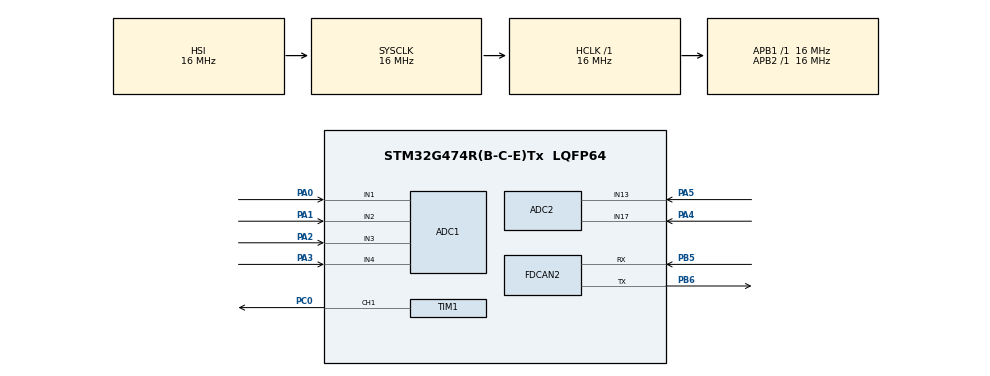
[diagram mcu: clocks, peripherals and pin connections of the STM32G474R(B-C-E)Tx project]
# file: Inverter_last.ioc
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ADC1.Channel-0\#ChannelRegularConversion=ADC_CHANNEL_1
ADC1.Channel-1\#ChannelRegularConversion=ADC_CHANNEL_2
ADC1.Channel-2\#ChannelRegularConversion=ADC_CHANNEL_3
ADC1.Channel-3\#ChannelRegularConversion=ADC_CHANNEL_4
ADC1.NbrOfConversion=4
ADC1.NbrOfConversionFlag=1
ADC1.OffsetNumber-0\#ChannelRegularConversion=ADC_OFFSET_NONE
ADC1.OffsetNumber-1\#ChannelRegularConversion=ADC_OFFSET_NONE
ADC1.OffsetNumber-2\#ChannelRegularConversion=ADC_OFFSET_NONE
ADC1.OffsetNumber-3\#ChannelRegularConversion=ADC_OFFSET_NONE
ADC1.Rank-0\#ChannelRegularConversion=1
ADC1.Rank-1\#ChannelRegularConversion=2
ADC1.Rank-2\#ChannelRegularConversion=3
ADC1.Rank-3\#ChannelRegularConversion=4
ADC1.SamplingTime-0\#ChannelRegularConversion=ADC_SAMPLETIME_2CYCLES_5
ADC1.SamplingTime-1\#ChannelRegularConversion=ADC_SAMPLETIME_2CYCLES_5
ADC1.SamplingTime-2\#ChannelRegularConversion=ADC_SAMPLETIME_2CYCLES_5
ADC1.SamplingTime-3\#ChannelRegularConversion=ADC_SAMPLETIME_2CYCLES_5
ADC1.master=1
ADC2.Channel-0\#ChannelRegularConversion=ADC_CHANNEL_17
ADC2.Channel-1\#ChannelRegularConversion=ADC_CHANNEL_13
ADC2.ContinuousConvMode=ENABLE
ADC2.DMAContinuousRequests=ENABLE
ADC2.EOCSelection=ADC_EOC_SEQ_CONV
ADC2.NbrOfConversion=2
ADC2.NbrOfConversionFlag=1
ADC2.OffsetNumber-0\#ChannelRegularConversion=ADC_OFFSET_NONE
ADC2.OffsetNumber-1\#ChannelRegularConversion=ADC_OFFSET_NONE
ADC2.Rank-0\#ChannelRegularConversion=1
ADC2.Rank-1\#ChannelRegularConversion=2
ADC2.SamplingTime-0\#ChannelRegularConversion=ADC_SAMPLETIME_2CYCLES_5
ADC2.SamplingTime-1\#ChannelRegularConversion=ADC_SAMPLETIME_2CYCLES_5
Dma.ADC1.0.Direction=DMA_PERIPH_TO_MEMORY
Dma.ADC1.0.EventEnable=DISABLE
Dma.ADC1.0.Instance=DMA1_Channel1
Dma.ADC1.0.MemDataAlignment=DMA_MDATAALIGN_WORD
Dma.ADC1.0.MemInc=DMA_MINC_ENABLE
Dma.ADC1.0.Mode=DMA_NORMAL
Dma.ADC1.0.PeriphDataAlignment=DMA_PDATAALIGN_WORD
Dma.ADC1.0.PeriphInc=DMA_PINC_DISABLE
Dma.ADC1.0.Polarity=HAL_DMAMUX_REQ_GEN_RISING
Dma.ADC1.0.Priority=DMA_PRIORITY_LOW
Dma.ADC1.0.RequestNumber=1
Dma.ADC1.0.SignalID=NONE
Dma.ADC1.0.SyncEnable=DISABLE
Dma.ADC1.0.SyncPolarity=HAL_DMAMUX_SYNC_NO_EVENT
Dma.ADC1.0.SyncRequestNumber=1
Dma.ADC1.0.SyncSignalID=NONE
Dma.ADC2.1.Direction=DMA_PERIPH_TO_MEMORY
Dma.ADC2.1.EventEnable=DISABLE
Dma.ADC2.1.Instance=DMA1_Channel2
Dma.ADC2.1.MemDataAlignment=DMA_MDATAALIGN_WORD
Dma.ADC2.1.MemInc=DMA_MINC_ENABLE
Dma.ADC2.1.Mode=DMA_NORMAL
Dma.ADC2.1.PeriphDataAlignment=DMA_PDATAALIGN_WORD
Dma.ADC2.1.PeriphInc=DMA_PINC_DISABLE
Dma.ADC2.1.Polarity=HAL_DMAMUX_REQ_GEN_RISING
Dma.ADC2.1.Priority=DMA_PRIORITY_LOW
Dma.ADC2.1.RequestNumber=1
Dma.ADC2.1.SignalID=NONE
Dma.ADC2.1.SyncEnable=DISABLE
Dma.ADC2.1.SyncPolarity=HAL_DMAMUX_SYNC_NO_EVENT
Dma.ADC2.1.SyncRequestNumber=1
Dma.ADC2.1.SyncSignalID=NONE
Dma.Request0=ADC1
Dma.Request1=ADC2
FDCAN2.CalculateBaudRateNominal=200000
FDCAN2.CalculateTimeBitNominal=5000
FDCAN2.CalculateTimeQuantumNominal=1000.0
FREERTOS.Tasks01=defaultTask,0,128,StartDefaultTask,Default,NULL,Dynamic,NULL,NULL;myTask02,-3,128,StartTask02,Default,NULL,Dynamic,NULL,NULL
FREERTOS.configUSE_NEWLIB_REENTRANT=1
Mcu.Family=STM32G4
Mcu.Name=STM32G474R(B-C-E)Tx
Mcu.Package=LQFP64
NVIC.DMA1_Channel1_IRQn=true\:5\:0\:false\:false\:true\:true\:false\:true\:true
NVIC.DMA1_Channel2_IRQn=true\:5\:0\:false\:false\:true\:true\:false\:true\:true
NVIC.PriorityGroup=NVIC_PRIORITYGROUP_4
PA0.Mode=IN1-Single-Ended
PA0.Signal=ADC1_IN1
PA1.Mode=IN2-Single-Ended
PA1.Signal=ADC1_IN2
PA2.Mode=IN3-Single-Ended
PA2.Signal=ADC1_IN3
PA3.Mode=IN4-Single-Ended
PA3.Signal=ADC1_IN4
PA4.Mode=IN17-Single-Ended
PA4.Signal=ADC2_IN17
PA5.Mode=IN13-Single-Ended
PA5.Signal=ADC2_IN13
PB5.Mode=FDCAN_Activate
PB5.Signal=FDCAN2_RX
PB6.Mode=FDCAN_Activate
PB6.Signal=FDCAN2_TX
PC0.Signal=S_TIM1_CH1
ProjectManager.HeapSize=0x200
ProjectManager.StackSize=0x400
ProjectManager.TargetToolchain=STM32CubeIDE
RCC.AHBFreq_Value=16000000
RCC.APB1Freq_Value=16000000
RCC.APB1TimFreq_Value=16000000
RCC.APB2Freq_Value=16000000
RCC.APB2TimFreq_Value=16000000
RCC.CortexFreq_Value=16000000
RCC.EXTERNAL_CLOCK_VALUE=12288000
RCC.HCLKFreq_Value=16000000
RCC.HSE_VALUE=8000000
RCC.HSI48_VALUE=48000000
RCC.HSI_VALUE=16000000
RCC.LSE_VALUE=32768
RCC.SYSCLKFreq_VALUE=16000000
RCC.USBFreq_Value=64000000
RCC.VCOOutputFreq_Value=128000000
SH.S_TIM1_CH1.0=TIM1_CH1,PWM Generation1 CH1
TIM1.Channel-PWM\ Generation1\ CH1=TIM_CHANNEL_1
VP_FREERTOS_VS_CMSIS_V1.Mode=CMSIS_V1
VP_SYS_VS_DBSignals.Mode=DisableDeadBatterySignals
board=custom

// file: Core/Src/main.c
/* USER CODE BEGIN Header */
/**
  ******************************************************************************
  * @file           : main.c
  * @brief          : Main program body
  ******************************************************************************
  * @attention
  *
  * Copyright (c) 2024 STMicroelectronics.
  * All rights reserved.
  *
  * This software is licensed under terms that can be found in the LICENSE file
  * in the root directory of this software component.
  * If no LICENSE file comes with this software, it is provided AS-IS.
  *
  ******************************************************************************
  */
/* USER CODE END Header */
#include "main.h"
#include "cmsis_os.h"

ADC_HandleTypeDef hadc1;
ADC_HandleTypeDef hadc2;
DMA_HandleTypeDef hdma_adc1;
DMA_HandleTypeDef hdma_adc2;

FDCAN_HandleTypeDef hfdcan2;

TIM_HandleTypeDef htim1;

osThreadId defaultTaskHandle;
osThreadId myTask02Handle;

void SystemClock_Config(void);
static void MX_GPIO_Init(void);
static void MX_DMA_Init(void);
static void MX_ADC1_Init(void);
static void MX_ADC2_Init(void);
static void MX_TIM1_Init(void);
static void MX_FDCAN2_Init(void);
void StartDefaultTask(void const * argument);
void StartTask02(void const * argument);

uint32_t adc_values[6];
uint32_t txData[6];
/* USER CODE END PFP */
int flag;
int a;
int b;
int c;
int d = 1;
int e;
int Cycle;

int main(void)
{

  /* MCU Configuration--------------------------------------------------------*/

  /* Reset of all peripherals, Initializes the Flash interface and the Systick. */
  HAL_Init();

  /* Configure the system clock */
  SystemClock_Config();

  /* Initialize all configured peripherals */
  MX_GPIO_Init();
  MX_DMA_Init();
  MX_ADC1_Init();
  MX_ADC2_Init();
  MX_TIM1_Init();
  MX_FDCAN2_Init();

  /* Create the thread(s) */
  /* definition and creation of defaultTask */
  osThreadDef(defaultTask, StartDefaultTask, osPriorityNormal, 0, 128);
  defaultTaskHandle = osThreadCreate(osThread(defaultTask), NULL);

  /* definition and creation of myTask02 */
  osThreadDef(myTask02, StartTask02, osPriorityIdle, 0, 128);
  myTask02Handle = osThreadCreate(osThread(myTask02), NULL);

  a++;

  /* Start scheduler */
  osKernelStart();

  /* We should never get here as control is now taken by the scheduler */

  /* Infinite loop */
  while (1)
  {

  }
}

void SystemClock_Config(void)
{
  RCC_OscInitTypeDef RCC_OscInitStruct = {0};
  RCC_ClkInitTypeDef RCC_ClkInitStruct = {0};

  /** Configure the main internal regulator output voltage
  */
  HAL_PWREx_ControlVoltageScaling(PWR_REGULATOR_VOLTAGE_SCALE1);

  /** Initializes the RCC Oscillators according to the specified parameters
  * in the RCC_OscInitTypeDef structure.
  */
  RCC_OscInitStruct.OscillatorType = RCC_OSCILLATORTYPE_HSI;
  RCC_OscInitStruct.HSIState = RCC_HSI_ON;
  RCC_OscInitStruct.HSICalibrationValue = RCC_HSICALIBRATION_DEFAULT;
  RCC_OscInitStruct.PLL.PLLState = RCC_PLL_NONE;
  if (HAL_RCC_OscConfig(&RCC_OscInitStruct) != HAL_OK)
  {
    Error_Handler();
  }

  /** Initializes the CPU, AHB and APB buses clocks
  */
  RCC_ClkInitStruct.ClockType = RCC_CLOCKTYPE_HCLK|RCC_CLOCKTYPE_SYSCLK
                              |RCC_CLOCKTYPE_PCLK1|RCC_CLOCKTYPE_PCLK2;
  RCC_ClkInitStruct.SYSCLKSource = RCC_SYSCLKSOURCE_HSI;
  RCC_ClkInitStruct.AHBCLKDivider = RCC_SYSCLK_DIV1;
  RCC_ClkInitStruct.APB1CLKDivider = RCC_HCLK_DIV1;
  RCC_ClkInitStruct.APB2CLKDivider = RCC_HCLK_DIV1;

  if (HAL_RCC_ClockConfig(&RCC_ClkInitStruct, FLASH_LATENCY_0) != HAL_OK)
  {
    Error_Handler();
  }
}

static void MX_ADC1_Init(void)
{

  ADC_MultiModeTypeDef multimode = {0};
  ADC_ChannelConfTypeDef sConfig = {0};

  /** Common config
  */
  hadc1.Instance = ADC1;
  hadc1.Init.ClockPrescaler = ADC_CLOCK_SYNC_PCLK_DIV2;
  hadc1.Init.Resolution = ADC_RESOLUTION_12B;
  hadc1.Init.DataAlign = ADC_DATAALIGN_RIGHT;
  hadc1.Init.GainCompensation = 0;
  hadc1.Init.ScanConvMode = ADC_SCAN_ENABLE;
  hadc1.Init.EOCSelection = ADC_EOC_SINGLE_CONV;
  hadc1.Init.LowPowerAutoWait = DISABLE;
  hadc1.Init.ContinuousConvMode = DISABLE;
  hadc1.Init.NbrOfConversion = 4;
  hadc1.Init.DiscontinuousConvMode = DISABLE;
  hadc1.Init.ExternalTrigConv = ADC_SOFTWARE_START;
  hadc1.Init.ExternalTrigConvEdge = ADC_EXTERNALTRIGCONVEDGE_NONE;
  hadc1.Init.DMAContinuousRequests = DISABLE;
  hadc1.Init.Overrun = ADC_OVR_DATA_PRESERVED;
  hadc1.Init.OversamplingMode = DISABLE;
  if (HAL_ADC_Init(&hadc1) != HAL_OK)
  {
    Error_Handler();
  }

  /** Configure the ADC multi-mode
  */
  multimode.Mode = ADC_MODE_INDEPENDENT;
  if (HAL_ADCEx_MultiModeConfigChannel(&hadc1, &multimode) != HAL_OK)
  {
    Error_Handler();
  }

  /** Configure Regular Channel
  */
  sConfig.Channel = ADC_CHANNEL_1;
  sConfig.Rank = ADC_REGULAR_RANK_1;
  sConfig.SamplingTime = ADC_SAMPLETIME_2CYCLES_5;
  sConfig.SingleDiff = ADC_SINGLE_ENDED;
  sConfig.OffsetNumber = ADC_OFFSET_NONE;
  sConfig.Offset = 0;
  if (HAL_ADC_ConfigChannel(&hadc1, &sConfig) != HAL_OK)
  {
    Error_Handler();
  }

  /** Configure Regular Channel
  */
  sConfig.Channel = ADC_CHANNEL_2;
  sConfig.Rank = ADC_REGULAR_RANK_2;
  if (HAL_ADC_ConfigChannel(&hadc1, &sConfig) != HAL_OK)
  {
    Error_Handler();
  }

  /** Configure Regular Channel
  */
  sConfig.Channel = ADC_CHANNEL_3;
  sConfig.Rank = ADC_REGULAR_RANK_3;
  if (HAL_ADC_ConfigChannel(&hadc1, &sConfig) != HAL_OK)
  {
    Error_Handler();
  }

  /** Configure Regular Channel
  */
  sConfig.Channel = ADC_CHANNEL_4;
  sConfig.Rank = ADC_REGULAR_RANK_4;
  if (HAL_ADC_ConfigChannel(&hadc1, &sConfig) != HAL_OK)
  {
    Error_Handler();
  }

}

static void MX_ADC2_Init(void)
{

  ADC_ChannelConfTypeDef sConfig = {0};

  /** Common config
  */
  hadc2.Instance = ADC2;
  hadc2.Init.ClockPrescaler = ADC_CLOCK_SYNC_PCLK_DIV2;
  hadc2.Init.Resolution = ADC_RESOLUTION_12B;
  hadc2.Init.DataAlign = ADC_DATAALIGN_RIGHT;
  hadc2.Init.GainCompensation = 0;
  hadc2.Init.ScanConvMode = ADC_SCAN_ENABLE;
  hadc2.Init.EOCSelection = ADC_EOC_SEQ_CONV;
  hadc2.Init.LowPowerAutoWait = DISABLE;
  hadc2.Init.ContinuousConvMode = ENABLE;
  hadc2.Init.NbrOfConversion = 2;
  hadc2.Init.DiscontinuousConvMode = DISABLE;
  hadc2.Init.ExternalTrigConv = ADC_SOFTWARE_START;
  hadc2.Init.ExternalTrigConvEdge = ADC_EXTERNALTRIGCONVEDGE_NONE;
  hadc2.Init.DMAContinuousRequests = ENABLE;
  hadc2.Init.Overrun = ADC_OVR_DATA_PRESERVED;
  hadc2.Init.OversamplingMode = DISABLE;
  if (HAL_ADC_Init(&hadc2) != HAL_OK)
  {
    Error_Handler();
  }

  /** Configure Regular Channel
  */
  sConfig.Channel = ADC_CHANNEL_17;
  sConfig.Rank = ADC_REGULAR_RANK_1;
  sConfig.SamplingTime = ADC_SAMPLETIME_2CYCLES_5;
  sConfig.SingleDiff = ADC_SINGLE_ENDED;
  sConfig.OffsetNumber = ADC_OFFSET_NONE;
  sConfig.Offset = 0;
  if (HAL_ADC_ConfigChannel(&hadc2, &sConfig) != HAL_OK)
  {
    Error_Handler();
  }

  /** Configure Regular Channel
  */
  sConfig.Channel = ADC_CHANNEL_13;
  sConfig.Rank = ADC_REGULAR_RANK_2;
  if (HAL_ADC_ConfigChannel(&hadc2, &sConfig) != HAL_OK)
  {
    Error_Handler();
  }

}

static void MX_FDCAN2_Init(void)
{

  hfdcan2.Instance = FDCAN2;
  hfdcan2.Init.ClockDivider = FDCAN_CLOCK_DIV1;
  hfdcan2.Init.FrameFormat = FDCAN_FRAME_CLASSIC;
  hfdcan2.Init.Mode = FDCAN_MODE_NORMAL;
  hfdcan2.Init.AutoRetransmission = DISABLE;
  hfdcan2.Init.TransmitPause = DISABLE;
  hfdcan2.Init.ProtocolException = DISABLE;
  hfdcan2.Init.NominalPrescaler = 16;
  hfdcan2.Init.NominalSyncJumpWidth = 1;
  hfdcan2.Init.NominalTimeSeg1 = 2;
  hfdcan2.Init.NominalTimeSeg2 = 2;
  hfdcan2.Init.DataPrescaler = 1;
  hfdcan2.Init.DataSyncJumpWidth = 1;
  hfdcan2.Init.DataTimeSeg1 = 1;
  hfdcan2.Init.DataTimeSeg2 = 1;
  hfdcan2.Init.StdFiltersNbr = 0;
  hfdcan2.Init.ExtFiltersNbr = 0;
  hfdcan2.Init.TxFifoQueueMode = FDCAN_TX_FIFO_OPERATION;
  if (HAL_FDCAN_Init(&hfdcan2) != HAL_OK)
  {
    Error_Handler();
  }

}

static void MX_TIM1_Init(void)
{

  TIM_MasterConfigTypeDef sMasterConfig = {0};
  TIM_OC_InitTypeDef sConfigOC = {0};
  TIM_BreakDeadTimeConfigTypeDef sBreakDeadTimeConfig = {0};

  htim1.Instance = TIM1;
  htim1.Init.Prescaler = 0;
  htim1.Init.CounterMode = TIM_COUNTERMODE_UP;
  htim1.Init.Period = 65535;
  htim1.Init.ClockDivision = TIM_CLOCKDIVISION_DIV1;
  htim1.Init.RepetitionCounter = 0;
  htim1.Init.AutoReloadPreload = TIM_AUTORELOAD_PRELOAD_DISABLE;
  if (HAL_TIM_PWM_Init(&htim1) != HAL_OK)
  {
    Error_Handler();
  }
  sMasterConfig.MasterOutputTrigger = TIM_TRGO_RESET;
  sMasterConfig.MasterOutputTrigger2 = TIM_TRGO2_RESET;
  sMasterConfig.MasterSlaveMode = TIM_MASTERSLAVEMODE_DISABLE;
  if (HAL_TIMEx_MasterConfigSynchronization(&htim1, &sMasterConfig) != HAL_OK)
  {
    Error_Handler();
  }
  sConfigOC.OCMode = TIM_OCMODE_PWM1;
  sConfigOC.Pulse = 0;
  sConfigOC.OCPolarity = TIM_OCPOLARITY_HIGH;
  sConfigOC.OCNPolarity = TIM_OCNPOLARITY_HIGH;
  sConfigOC.OCFastMode = TIM_OCFAST_DISABLE;
  sConfigOC.OCIdleState = TIM_OCIDLESTATE_RESET;
  sConfigOC.OCNIdleState = TIM_OCNIDLESTATE_RESET;
  if (HAL_TIM_PWM_ConfigChannel(&htim1, &sConfigOC, TIM_CHANNEL_1) != HAL_OK)
  {
    Error_Handler();
  }
  sBreakDeadTimeConfig.OffStateRunMode = TIM_OSSR_DISABLE;
  sBreakDeadTimeConfig.OffStateIDLEMode = TIM_OSSI_DISABLE;
  sBreakDeadTimeConfig.LockLevel = TIM_LOCKLEVEL_OFF;
  sBreakDeadTimeConfig.DeadTime = 0;
  sBreakDeadTimeConfig.BreakState = TIM_BREAK_DISABLE;
  sBreakDeadTimeConfig.BreakPolarity = TIM_BREAKPOLARITY_HIGH;
  sBreakDeadTimeConfig.BreakFilter = 0;
  sBreakDeadTimeConfig.BreakAFMode = TIM_BREAK_AFMODE_INPUT;
  sBreakDeadTimeConfig.Break2State = TIM_BREAK2_DISABLE;
  sBreakDeadTimeConfig.Break2Polarity = TIM_BREAK2POLARITY_HIGH;
  sBreakDeadTimeConfig.Break2Filter = 0;
  sBreakDeadTimeConfig.Break2AFMode = TIM_BREAK_AFMODE_INPUT;
  sBreakDeadTimeConfig.AutomaticOutput = TIM_AUTOMATICOUTPUT_DISABLE;
  if (HAL_TIMEx_ConfigBreakDeadTime(&htim1, &sBreakDeadTimeConfig) != HAL_OK)
  {
    Error_Handler();
  }
  HAL_TIM_MspPostInit(&htim1);

}

static void MX_DMA_Init(void)
{

  /* DMA controller clock enable */
  __HAL_RCC_DMAMUX1_CLK_ENABLE();
  __HAL_RCC_DMA1_CLK_ENABLE();

  /* DMA interrupt init */
  /* DMA1_Channel1_IRQn interrupt configuration */
  HAL_NVIC_SetPriority(DMA1_Channel1_IRQn, 5, 0);
  HAL_NVIC_EnableIRQ(DMA1_Channel1_IRQn);
  /* DMA1_Channel2_IRQn interrupt configuration */
  HAL_NVIC_SetPriority(DMA1_Channel2_IRQn, 5, 0);
  HAL_NVIC_EnableIRQ(DMA1_Channel2_IRQn);

}

static void MX_GPIO_Init(void)
{

  /* GPIO Ports Clock Enable */
  __HAL_RCC_GPIOC_CLK_ENABLE();
  __HAL_RCC_GPIOA_CLK_ENABLE();
  __HAL_RCC_GPIOB_CLK_ENABLE();

}

void FDCAN_Transmit(uint32_t *data, uint8_t length) {
    FDCAN_TxHeaderTypeDef txHeader;
    c++;

    // Fill TxHeader
    txHeader.Identifier = 0x123; // Example CAN ID
    txHeader.IdType = FDCAN_STANDARD_ID;
    txHeader.TxFrameType = FDCAN_DATA_FRAME;
    txHeader.DataLength = FDCAN_DLC_BYTES_8;
    txHeader.ErrorStateIndicator = FDCAN_ESI_ACTIVE;
    txHeader.BitRateSwitch = FDCAN_BRS_ON;
    txHeader.FDFormat = FDCAN_FD_CAN;
    txHeader.TxEventFifoControl = FDCAN_NO_TX_EVENTS;
    txHeader.MessageMarker = 0;

    // Copy data into txData (convert to bytes)
    for (uint8_t i = 0; i < length && i < 8; i++) {
        txData[i] = (uint8_t)(data[i] & 0xFF);
    }

    // Transmit
    if (HAL_FDCAN_AddMessageToTxFifoQ(&hfdcan2, &txHeader, (uint8_t *)txData) != HAL_OK) {
        flag = 1;
    }
    e++;
}

void Read_ADC_And_Send(void) {
	FDCAN_Transmit((uint32_t *)adc_values, 6);
}

void Set_PWM_DutyCycle(uint16_t dutyCycle) {
    if (dutyCycle > 65535) {
        dutyCycle = 65535;
    }
    __HAL_TIM_SET_COMPARE(&htim1, TIM_CHANNEL_1, dutyCycle);
}

void StartDefaultTask(void const * argument)
{
  /* USER CODE BEGIN 5 */
	HAL_ADC_Start_DMA(&hadc1, (uint32_t *)adc_values, 5);
	HAL_ADC_Start_DMA(&hadc2, (uint32_t *)(adc_values + 5), 2);
  /* Infinite loop */
  for(;;)
  {
	  Read_ADC_And_Send();
    osDelay(1);
  }
  /* USER CODE END 5 */
}

void StartTask02(void const * argument)
{
  for(;;)
  {
    osDelay(1);
  }
}

void Error_Handler(void)
{
  __disable_irq();
  while (1)
  {
  }
}
